# CC23x0 register map
File version: 1.0
CPU: CM0+ r0p4, little endian, no MPU, no FPU, VTOR, 3 interrupt priority bits
Registers are 32-bit, read-write, reset 0x0 unless marked. A register's access mark holds for its fields unless they carry their own. Offsets are from the block's base; [hi:lo] are bit positions; lines under a group give offsets from that group; {n}, {i} and the like mark numbered series; 'fields as' and 'values as' point back to an identical list.

## IOC — IO Controller
Base 0x40003000
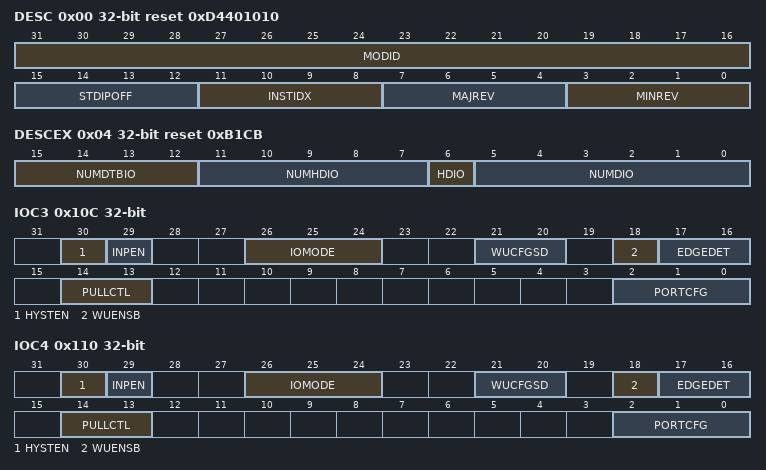
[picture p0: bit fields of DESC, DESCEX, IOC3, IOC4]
0x00 DESC ro reset 0xD4401010 — This register identifies the peripheral and its exact version.
  [31:16] MODID — Module identification contains a unique peripheral identification number.
    0xFFFF=MAXIMUM (Highest possible value); 0=MINIMUM (Smallest value)
  [15:12] STDIPOFF — Standard IP registers offset. Value 0 indicates Standard IP registers are not present. Any other value between 1 to 15 indicates standard IP registers start from address offset 64 * STDIPOFF from base address.
    15=MAXIMUM (Highest possible value); 0=MINIMUM (Smallest value)
  [11:8] INSTIDX — Instance Index within the device. This will be a parameter to the RTL for modules that can have multiple instances.
    values as STDIPOFF
  [7:4] MAJREV — Major rev of the IP
    values as STDIPOFF
  [3:0] MINREV — Minor rev of the IP
    values as STDIPOFF
0x04 DESCEX ro reset 0xB1CB — This register describes the configuration of IOC.
  [15:12] NUMDTBIO — Number of DTB IOs supported. Total DTB IOs supported is NUMDTBIO value +1.
    values as DESC.STDIPOFF
  [11:7] NUMHDIO — Number of HD IOs supported. Total HD IOs supported is NUMHDIO value +1.
    31=MAXIMUM (Highest possible value); 0=MINIMUM (Smallest value)
  [6] HDIO — High drive IO supported by IOC.
    1=PRESENT (HD IO supported by IOC); 0=ABSENT (HD IO not supported by IOC)
  [5:0] NUMDIO — Number of DIOs supported. Total DIOs supported is NUMDIO value +1.
    63=MAXIMUM (Highest possible value); 0=MINIMUM (Smallest value)
0x64 DTB — Digital Test Bus. This register is used to bring out some internal signals of the peripheral on digital test bus (DTB).
  [2:0] SEL — This bit field is used to select DTB mux digital output signals.
    {v}=GRP{v} (Selects test group {v}) (v=1..7); 0=DISABLE (DTB output from peripheral is 0x0)
0x10C IOC3 — Configuration
  [30] HYSTEN — Input hysteresis enable
    1=ENABLE (Input hysteresis enabled); 0=DISABLE (Input hysteresis disabled)
  [29] INPEN — Input enable
    1=ENABLE (Input enabled); 0=DISABLE (Input disabled)
  [26:24] IOMODE — IO Mode. Setting this to value 0x6 or 0x7 will default to normal IO behavior.
    5=OPENS_INV (Open Source, inverted IO); 4=OPENS (Open Source, normal IO); 3=OPEND_INV (Open Drain, inverted IO); 2=OPEND (Open Drain, normal IO); 1=INVERTED (Inverted IO); 0=NORMAL (Normal IO)
  [21:20] WUCFGSD — Wakeup configuration from shutdown
    3=WAKE_HIGH (wakeup triggered when pad level is high); 2=WAKE_LOW (wakeup triggered when pad level is low); 1=DISABLED_1 (wakeup disabled); 0=DISABLED_0 (wakeup disabled)
  [18] WUENSB — Wakeup enable from standby
    1=ENABLE (wakeup enabled (effective only if EDGEDET is enabled)); 0=DISABLE (wakeup disabled)
  [17:16] EDGEDET — Edge detect configuration
    3=EDGE_BOTH (Positive and negative edge detection); 2=EDGE_POS (Positive edge detection); 1=EDGE_NEG (Negative edge detection); 0=EDGE_DIS (No edge detection)
  [14:13] PULLCTL — Pull control. Setting this to value 0x3 disables pull.
    2=PULL_UP (Pull up enabled); 1=PULL_DOWN (Pull down enabled); 0=PULL_DIS (No pull)
  [2:0] PORTCFG — Port configuration.
    7=DTB (Digital Test Bus function); 6=ANA (Analog function); {v}=PFUNC{v} (Digital peripheral function-{v}) (v=1..5); 0=BASE (Base function)
0x110 IOC4 — Configuration
  fields as IOC3
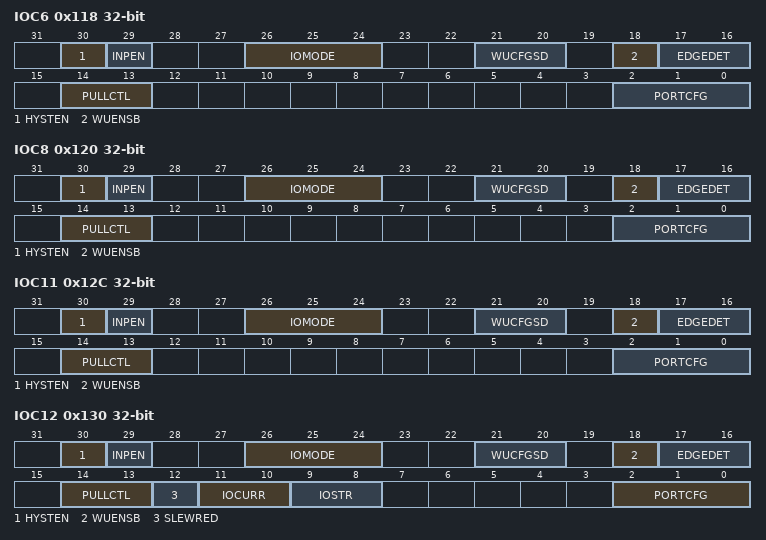
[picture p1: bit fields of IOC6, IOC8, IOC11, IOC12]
0x118 IOC6 — Configuration
  fields as IOC3
0x120 IOC8 — Configuration
  fields as IOC3
0x12C IOC11 — Configuration
  fields as IOC3
0x130 IOC12 — Configuration
  [30] HYSTEN — Input hysteresis enable
    values as IOC3.HYSTEN
  [29] INPEN — Input enable
    1=ENABLE (Input enabled); 0=DISABLE (Input disabled)
  [26:24] IOMODE — IO Mode. Setting this to value 0x6 or 0x7 will default to normal IO behavior.
    values as IOC3.IOMODE
  [21:20] WUCFGSD — Wakeup configuration from shutdown
    values as IOC3.WUCFGSD
  [18] WUENSB — Wakeup enable from standby
    values as IOC3.WUENSB
  [17:16] EDGEDET — Edge detect configuration
    values as IOC3.EDGEDET
  [14:13] PULLCTL — Pull control. Setting this to value 0x3 disables pull.
    values as IOC3.PULLCTL
  [12] SLEWRED — Slew rate configuration
    1=REDUCED (Reduced slew rate); 0=NORMAL (Normal slew rate)
  [11:10] IOCURR — Output current configuration. Writing value 0x3 defaults to 2mA current setting.
    2=CUR_8MA (8mA); 1=CUR_4MA (4mA); 0=CUR_2MA (2mA)
  [9:8] IOSTR — Drive strength configuration
    3=MAX (Maximum drive strength); 2=MEDIUM (Medium drive strength); 1=MIN (Minimum drive stregnth); 0=AUTO (Automatic drive strength adjustment)
  [2:0] PORTCFG — Port configuration.
    values as IOC3.PORTCFG
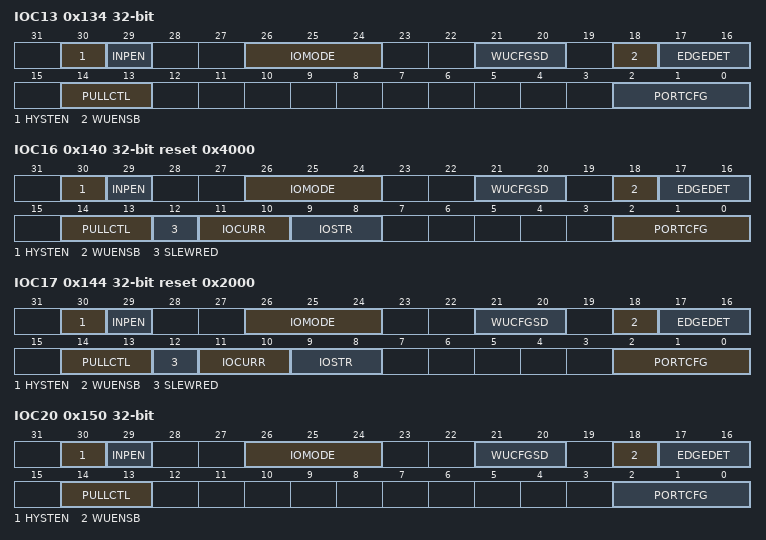
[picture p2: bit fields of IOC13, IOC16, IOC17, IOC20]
0x134 IOC13 — Configuration
  fields as IOC3
0x140 IOC16 reset 0x4000 — Configuration
  fields as IOC12
0x144 IOC17 reset 0x2000 — Configuration
  fields as IOC12
0x150 IOC20 — Configuration
  fields as IOC3
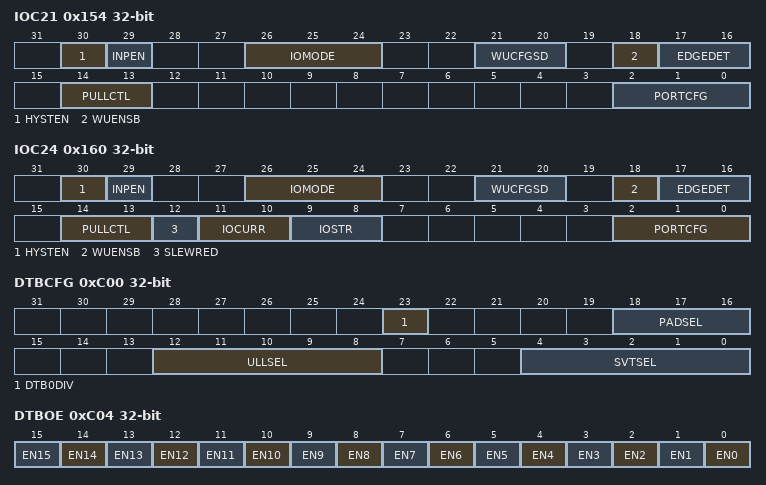
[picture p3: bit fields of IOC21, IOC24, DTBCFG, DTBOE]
0x154 IOC21 — Configuration
  fields as IOC3
0x160 IOC24 — Configuration
  fields as IOC12
0xC00 DTBCFG — DTB configuration
  [23] DTB0DIV — This bit is used to divide DTB[0] output by 8.
    1=ENABLE (Divide DTB[0] output by 8); 0=DISABLE (No divide)
  [18:16] PADSEL — Selects which 3 DTB lines out of total 16 are routed to DTB pins 15 to 13.
    5=DTB2TO0 (DTB[2:0] selected); 4=DTB5TO3 (DTB[5:3] selected); 3=DTB8TO6 (DTB[8:6] selected); 2=DTB11TO9 (DTB[11:9] selected); 1=DTB14TO12 (DTB[14:12] selected); 0=DTB15TO13 (DTB[15:13] selected)
  [12:8] ULLSEL — ULL DTB Mux selection
    31=MAXIMUM (Maximum value); 0=MINIMUM (Minimum value)
  [4:0] SVTSEL — SVT DTB Mux selection
    31=MAXIMUM (Maximum value); 0=MINIMUM (Minimum value)
0xC04 DTBOE — DTB output enable
  [all] fields
    1=ENABLE (DTB output enabled); 0=DISABLE (DTB output disabled)
  [n] EN{n} (n=0..15) — Enables DTB output {n}
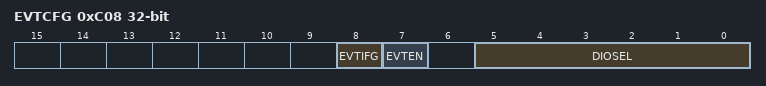
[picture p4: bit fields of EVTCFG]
0xC08 EVTCFG — Event configuration. This register is used to select DIO for IOC to publish event on AON event fabric. It also contains enable bit that is used to mask the event and event flag bit.
  [8] EVTIFG — Event flag. It is set when edge is detected on selected DIO. Note: The edge detector flop is cleared for the selected DIO when EVTIFG is cleared by software.
    1=SET; 0=CLR (Clear)
  [7] EVTEN — Enables IOC to publish event on AON event fabric when EVTIFG is set.
    1=ENABLE; 0=DISABLE
  [5:0] DIOSEL — This is used to select DIO for event generation. For example, DIOSEL = 0x0 selects DIO0 and DIOSEL = 0x8 selects DIO8.
    63=MAXIMUM (Maximum value); 0=MINIMUM (Minimum value)
0xC0C TEST
  [0] SEL — This is used to drive SWDIO output data and output enable from debug sub-system onto DIO12 (TDO) pad.
    1=HIGH (Output data and output enable driven based on debug sub-system inputs); 0=LOW (Output data and output enable managed by IOC)
0xC10 DTBSTAT ro — DTB status register.
  [15:0] VAL — This bit field captures the final 16-bit value of DTB signals provided from IOC to DTB device pins.
